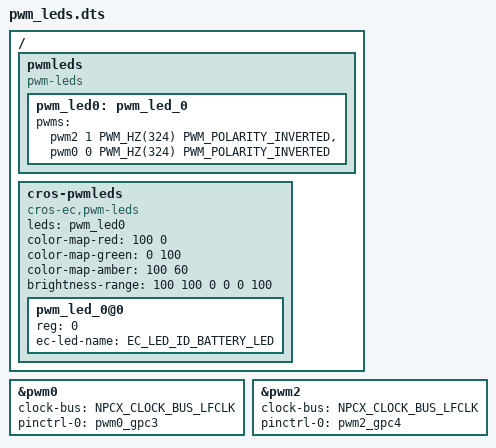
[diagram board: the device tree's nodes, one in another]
/* Copyright 2022 The Chromium OS Authors. All rights reserved.
 * Use of this source code is governed by a BSD-style license that can be
 * found in the LICENSE file.
 */

/ {
	pwmleds {
		compatible = "pwm-leds";
		pwm_led0: pwm_led_0 {
			pwms = <&pwm2 1 PWM_HZ(324) PWM_POLARITY_INVERTED>,
			       <&pwm0 0 PWM_HZ(324) PWM_POLARITY_INVERTED>;
		};
	};

	cros-pwmleds {
		compatible = "cros-ec,pwm-leds";

		leds = <&pwm_led0>;

				/*<red green>*/
		color-map-red    = <100   0>;
		color-map-green  = <  0 100>;
		color-map-amber  = <100  60>;

		/* brightness-range = <red green blue yellow white amber> */
		brightness-range = <100 100 0 0 0 100>;

		#address-cells = <1>;
		#size-cells = <0>;

		pwm_led_0@0 {
			reg = <0>;
			ec-led-name = "EC_LED_ID_BATTERY_LED";
		};
	};
};

/* Enable LEDs to work while CPU suspended */

&pwm0 {
	status = "okay";
	clock-bus = "NPCX_CLOCK_BUS_LFCLK";
	pinctrl-0 = <&pwm0_gpc3>;
	pinctrl-names = "default";
};

&pwm2 {
	status = "okay";
	clock-bus = "NPCX_CLOCK_BUS_LFCLK";
	pinctrl-0 = <&pwm2_gpc4>;
	pinctrl-names = "default";
};
